# STM32H7B3 register map
File version: 3.3
CPU: CM7 r0p1, little endian, MPU, FPU, 4 interrupt priority bits
Registers are 32-bit, read-write, reset 0x0 unless marked. A register's access mark holds for its fields unless they carry their own. Offsets are from the block's base; [hi:lo] are bit positions; {n}, {i} and the like mark numbered series.

## DELAY_Block_SDMMC1
Base 0x52008000
Same registers: DELAY_Block_SDMMC2 0x48022800, Delay_Block_OCTOSPI1 0x52006000, Delay_Block_OCTOSPI2 0x5200B000
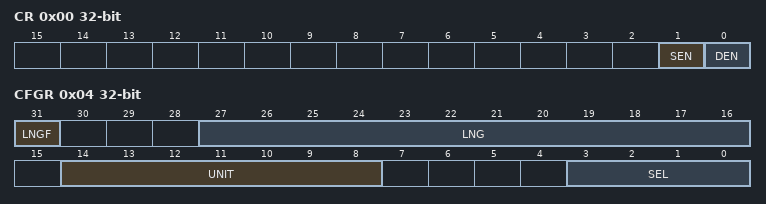
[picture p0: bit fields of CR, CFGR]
0x00 CR — DLYB control register
  [1] SEN — Sampler length enable bit
  [0] DEN — Delay block enable bit
0x04 CFGR — DLYB configuration register
  [31] LNGF — Length valid flag
  [27:16] LNG — Delay line length value
  [14:8] UNIT — Delay Defines the delay of a Unit delay cell
  [3:0] SEL — Select the phase for the Output clock

## HASH — Hash processor
Base 0x48021400
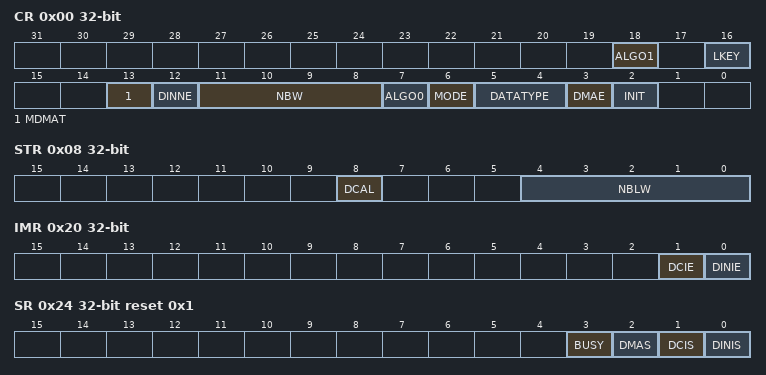
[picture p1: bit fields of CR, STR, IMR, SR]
0x00 CR access per field — control register
  [18] ALGO1 rw — ALGO
  [16] LKEY rw — Long key selection
  [13] MDMAT rw — Multiple DMA Transfers
  [12] DINNE ro — DIN not empty
  [11:8] NBW ro — Number of words already pushed
  [7] ALGO0 rw — Algorithm selection
  [6] MODE rw — Mode selection
  [5:4] DATATYPE rw — Data type selection
  [3] DMAE rw — DMA enable
  [2] INIT wo — Initialize message digest calculation
0x04 DIN — data input register
  [31:0] DATAIN — Data input
0x08 STR access per field — start register
  [8] DCAL wo — Digest calculation
  [4:0] NBLW rw — Number of valid bits in the last word of the message
{0xC+4i} HR{i} (i=0..4) ro — digest registers
  [31:0] H — H0
0x20 IMR — interrupt enable register
  [1] DCIE — Digest calculation completion interrupt enable
  [0] DINIE — Data input interrupt enable
0x24 SR access per field reset 0x1 — status register
  [3] BUSY ro — Busy bit
  [2] DMAS ro — DMA Status
  [1] DCIS rw — Digest calculation completion interrupt status
  [0] DINIS rw — Data input interrupt status
{0xF8+4i} CSR{i} (i=0..53) — context swap registers
  [31:0] CSR — CSR0
{0x310+4i} HASH_HR{i} (i=0..7) ro — HASH digest register {i}
  [31:0] H — H0

## HSEM
Base 0x48020800
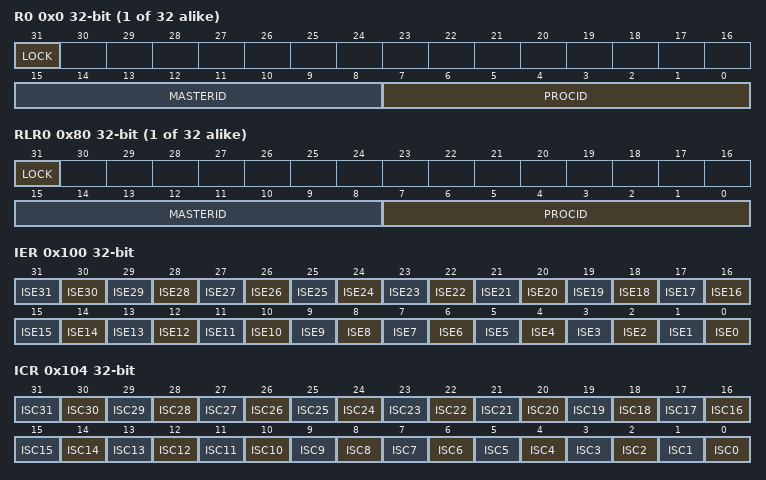
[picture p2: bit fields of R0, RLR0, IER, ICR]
{0x0+4i} R{i} (i=0..31) — HSEM register HSEM_R{i}
  [31] LOCK — Lock indication
    on read: 0=Free (Semaphore is free); 1=Locked (Semaphore is locked) | on write: 0=Free semaphore; 1=TryLock (Try to lock semaphore)
  [15:8] MASTERID range 0..15 — Semaphore MasterID
  [7:0] PROCID — Semaphore ProcessID
{0x80+4i} RLR{i} (i=0..31) ro — Semaphore {i} read lock register
  [31] LOCK — Lock indication
    0=Free (Semaphore is free); 1=Locked (Semaphore is locked)
  [15:8] MASTERID range 0..15 — Semaphore MasterID
  [7:0] PROCID — Semaphore ProcessID
0x100 IER — HSEM Interrupt enable register
  [n] ISE{n} (n=0..31) — Interrupt semaphore {n} enable bit
    0=Disabled (Interrupt generation disabled); 1=Enabled (Interrupt generation enabled)
0x104 ICR — HSEM Interrupt clear register
  [n] ISC{n} (n=0..31) — Interrupt semaphore {n} clear bit
    on read: 0=NoEffect (Always reads 0) | on write: 0=NoEffect (Interrupt semaphore x status ISFx and masked status MISFx not affected); 1=Clear (Interrupt semaphore x status ISFx and masked status MISFx cleared)
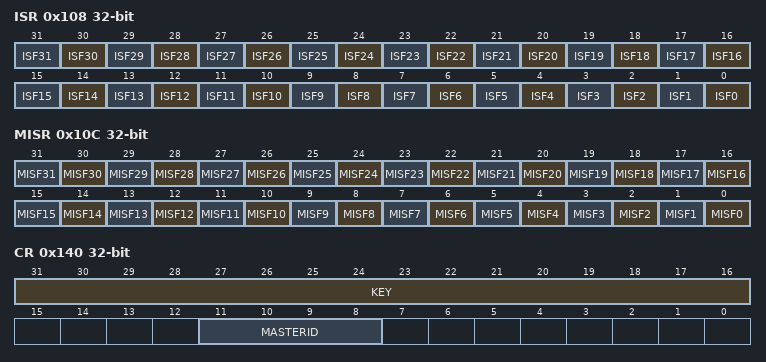
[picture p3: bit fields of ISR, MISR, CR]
0x108 ISR ro — HSEM Interrupt status register
  [n] ISF{n} (n=0..31) — Interrupt semaphore {n} status bit before enable (mask)
    0=NotPending (No interrupt pending); 1=Pending (Interrupt pending)
0x10C MISR ro — HSEM Masked interrupt status register
  [n] MISF{n} (n=0..31) — Masked interrupt semaphore {n} status bit after enable (mask)
    0=NotPending (No interrupt pending after masking); 1=Pending (Interrupt pending after masking)
0x140 CR — HSEM Clear register
  [31:16] KEY — Semaphore clear Key
  [11:8] MASTERID — MasterID of semaphores to be cleared
0x144 KEYR — HSEM Interrupt clear register
  [31:16] KEY — Semaphore Clear Key

## MDIOS — Management data input/output slave
Base 0x40009400
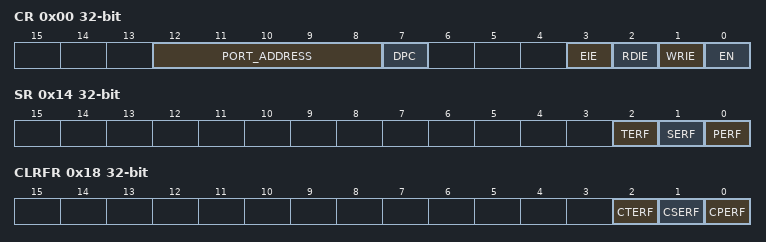
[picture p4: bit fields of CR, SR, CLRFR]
0x00 CR — MDIOS configuration register
  [12:8] PORT_ADDRESS — Slaves's address
  [7] DPC — Disable Preamble Check
  [3] EIE — Error interrupt enable
  [2] RDIE — Register Read Interrupt Enable
  [1] WRIE — Register write interrupt enable
  [0] EN — Peripheral enable
0x04 WRFR ro — MDIOS write flag register
  [31:0] WRF — Write flags for MDIO registers 0 to 31
0x08 CWRFR — MDIOS clear write flag register
  [31:0] CWRF — Clear the write flag
0x0C RDFR ro — MDIOS read flag register
  [31:0] RDF — Read flags for MDIO registers 0 to 31
0x10 CRDFR — MDIOS clear read flag register
  [31:0] CRDF — Clear the read flag
0x14 SR ro — MDIOS status register
  [2] TERF — Turnaround error flag
  [1] SERF — Start error flag
  [0] PERF — Preamble error flag
0x18 CLRFR — MDIOS clear flag register
  [2] CTERF — Clear the turnaround error flag
  [1] CSERF — Clear the start error flag
  [0] CPERF — Clear the preamble error flag
{0x1C+4i} DINR{i} ro (i=0..31) — MDIOS input data register {i}
  [15:0] DIN{i} — Input data received from MDIO Master during write frames
{0x9C+4i} DOUTR{i} (i=0..31) — MDIOS output data register {i}
  [15:0] DOUT{i} — Output data sent to MDIO Master during read frames
